# evalsoc register map
Vendor: Nuclei; Series: Nuclei Evaluation SoC
Nuclei Evaluation SoC using Nuclei N/NX Core
CPU: Evalsoc, little endian
Registers are 32-bit, read-write, reset 0x0 unless marked. A register's access mark holds for its fields unless they carry their own. Offsets are from the block's base; lines under a group give offsets from that group; [hi:lo] are bit positions; {n}, {i} and the like mark numbered series; 'fields as' and 'values as' point back to an identical list; <NAME> marks a mode.

## Memory map
0x10012000 GPIO0 size 0x1000 — General purpose input/output controller.
0x10013000 UART0 size 0x1000 — Universal Asynchronous Receiver/Transmitter.
0x10014000 QSPI0 size 0x1000 — Serial Peripheral Interface.
0x10023000 UART1 size 0x1000 — Universal Asynchronous Receiver/Transmitter.
0x10024000 QSPI1 size 0x1000 — Serial Peripheral Interface.
0x10034000 QSPI2 size 0x1000 — Serial Peripheral Interface.
0x18000000 IINFO — Some internal information is defined here by memory map registers. IINFO shows internal peripherals configurations or controls some micro-architecture functions.
0x18010000 DEBUG — Address space of DEBUG unit.
0x18020000 ECLIC — Enhanced Core Local Interrupt Controller (ECLIC) for fast interrupt handling.
0x18030000 TIMER — Address space of TIMER unit. The Timer Unit (TIMER) is used to generate the Timer Interrupt and Software Interrupt in Nuclei Processor Core.
0x18040000 SMP — Address space of SMP and Cluster Cache. Nuclei Processor Core can optionally support Cluster Cache (CC) and Symmetric Multi-Processor (SMP).
0x18050000 CIDU — Address space of CIDU unit. The Cluster Interrupt Distribution Unit (CIDU) is used to distribute external interrupts to the core's ECLIC, also provides Inter Core Interrupt (ICI) and Semaphores Mechanism.
0x1C000000 PLIC — Address space of PLIC unit. The Platform-Level Interrupt Controller (PLIC) is used for Linux capable applications or symmetric multi-processor (SMP) applications.

## Interrupts
3 UART0_IRQ (UART0)
4 UART1_IRQ (UART1)
5 QSPI0_IRQ (QSPI0)
6 QSPI1_IRQ (QSPI1)
7 QSPI2_IRQ (QSPI2)
{n+8} GPIO_{n}_IRQ (GPIO0) (n=0..12)
21 GPIO_12_IRQ (GPIO0)
22 GPIO_14_IRQ (GPIO0)
23 GPIO_14_IRQ (GPIO0)
{n+8} GPIO_{n}_IRQ (GPIO0) (n=16..28)
37 GPIO_28_IRQ (GPIO0)
38 GPIO_30_IRQ (GPIO0)
39 GPIO_31_IRQ (GPIO0)

## ECLIC — Enhanced Core Local Interrupt Controller (ECLIC) for fast interrupt handling.
Base 0x18020000
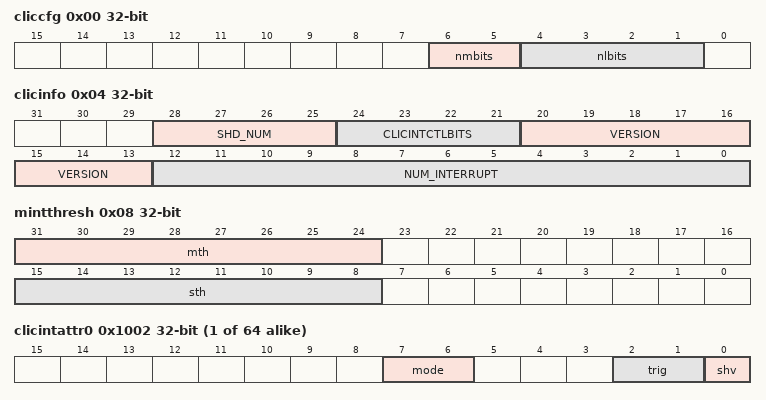
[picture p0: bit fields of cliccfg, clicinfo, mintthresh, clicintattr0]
0x00 cliccfg — Global configuration register for ECLIC.
  [6:5] nmbits ro — Ties to 1, indicates supervisor-level interrupt support.
  [4:1] nlbits — Specifies the bit-width of level and priority in clicintctl[0].
0x04 clicinfo ro — Global information register for ECLIC.
  [28:25] SHD_NUM — Shadow register group number for each privilege mode.
  [24:21] CLICINTCTLBITS — Effective bit-width of clicintctl[0].
  [20:13] VERSION — Hardware implementation version number.
  [12:0] NUM_INTERRUPT — Number of interrupt sources supported.
0x08 mintthresh — Interrupt threshold level register for M-mode and S-mode.
  [31:24] mth — Interrupt-level threshold for M-mode.
  [15:8] sth — Interrupt-level threshold for S-mode.
{0x1000+4i} clicintip{i} (i=0..63) — M-mode interrupt pending flag register for interrupt source i.
  [0] IP — Interrupt source pending flag.
{0x1001+4i} clicintie{i} (i=0..63) — M-mode interrupt enable register for interrupt source i.
  [0] IE — Interrupt enable bit.
{0x1002+4i} clicintattr{i} (i=0..63) — M-mode interrupt attribute register for interrupt source i.
  [7:6] mode — Privilege mode to take interrupt: 3=M-mode, 1=S-mode. Only 1 or 3 can be written, other values ignored.
  [2:1] trig — Trigger type: 0=level, 1=rising edge, 3=falling edge.
  [0] shv — Vectored mode: 1=vectored, 0=non-vectored.
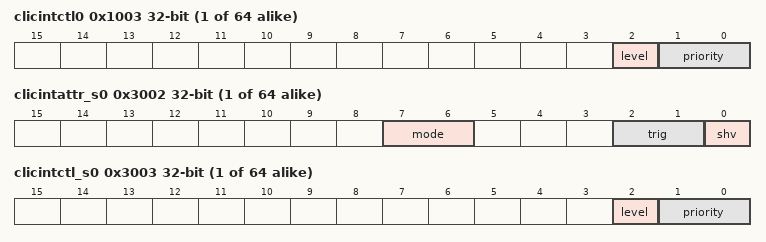
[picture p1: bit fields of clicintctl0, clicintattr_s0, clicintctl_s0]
{0x1003+4i} clicintctl{i} (i=0..63) — M-mode interrupt control register for interrupt source i. Used to set the level and priority.
  [2] level — Interrupt level. Higher value = higher priority, can preempt lower level interrupts. nlbits 1 is for calculation.
  [1:0] priority — Interrupt priority within the same level. Higher value = higher priority. Unimplemented low bits are tied to 1. nlbits 1 is for calculation.
0x2008 sintthresh — Interrupt threshold level register for S-mode. Mirror of mintthresh.sth.
  [15:8] sth — Interrupt-level threshold for S-mode. Mirror of mintthresh.sth.
{0x3000+4i} clicintip_s{i} (i=0..63) — S-mode interrupt pending flag register for interrupt source i. Only accessible for interrupts configured with mode=1.
  [0] IP — Interrupt source pending flag.
{0x3001+4i} clicintie_s{i} (i=0..63) — S-mode interrupt enable register for interrupt source i. Only accessible for interrupts configured with mode=1.
  [0] IE — Interrupt enable bit.
{0x3002+4i} clicintattr_s{i} (i=0..63) — S-mode interrupt attribute register for interrupt source i. Only accessible for interrupts configured with mode=1.
  [7:6] mode ro — Privilege mode (read-only in S-mode).
  [2:1] trig — Trigger type (only low 6 bits writable in S-mode).
  [0] shv — Vectored mode.
{0x3003+4i} clicintctl_s{i} (i=0..63) — S-mode interrupt control register for interrupt source i. Only accessible for interrupts configured with mode=1.
  fields as clicintctl0
